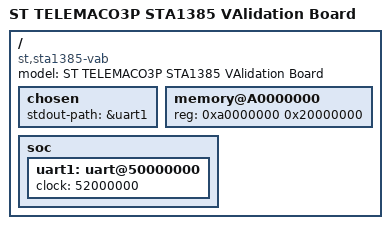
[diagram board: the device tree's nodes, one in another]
/*
 * Copyright (C) 2016 STMicroelectronics
 * Author: Julien Delacou <julien.delacou@st.com>
 *
 * This program is free software; you can redistribute it and/or modify
 * it under the terms of the GNU General Public License version 2, as
 * published by the Free Software Foundation.
 */

/dts-v1/;
#include "sta1295.dtsi"

/ {
	model = "ST TELEMACO3P STA1385 VAlidation Board";
	compatible = "st,sta1385-vab";

	chosen {
		stdout-path = &uart1;
	};

	memory@A0000000 {
		device_type = "memory";
		reg = <0xa0000000 0x20000000>;
	};

	soc {
		uart1: uart@50000000 {
			clock = <52000000>;
			status = "okay";
		};
	};
};
